AUTOSAR XML (schema 4-2-1)
package /MICROSAR/WdgM_swc/DataTypes
  5 x impl type, all with category=TYPE_REFERENCE:
    WdgM_SupervisedEntityIdType: range raw 0..65535, implementation-data-type=uint16  # Identifier of a supervised entity
    WdgM_CheckpointIdType: range raw 0..65535, implementation-data-type=uint16  # Identifier of a checkpoint
    WdgM_ModeType: range raw 0..255, implementation-data-type=uint8  # Identifier of the Watchdog trigger mode
    WdgM_LocalStatusType: compu {0=WDGM_LOCAL_STATUS_OK, 1=WDGM_LOCAL_STATUS_FAILED, 2=WDGM_LOCAL_STATUS_EXPIRED, 4=WDGM_LOCAL_STATUS_DEACTIVATED}, range raw 0..4, implementation-data-type=uint8  # Local Monitoring Status of a supervised entity.
    WdgM_GlobalStatusType: compu {0=WDGM_GLOBAL_STATUS_OK, 1=WDGM_GLOBAL_STATUS_FAILED, 2=WDGM_GLOBAL_STATUS_EXPIRED, 3=WDGM_GLOBAL_STATUS_STOPPED, 4=WDGM_GLOBAL_STATUS_DEACTIVATED}, range raw 0..4, implementation-data-type=uint8  # Global Monitoring Status summarizes all local monitoring statuses of all supervised entities.
package /MICROSAR/WdgM_swc/Interfaces
  client server interface WdgM_AliveSupervision: is-service=true, service-kind=WATCH-DOG-MANAGER
    operation CheckpointReached: possible-error=WdgM_AliveSupervision/E_NOT_OK  # Indicates to the Watchdog Manager that a Checkpoint within a Supervised Entity has been reached.
      arg CPID: type=WdgM_CheckpointIdType, direction=IN  # Identifier of the checkpoint within a supervised entity that has been reached.
    error E_NOT_OK: error-code=1
  client server interface WdgM_LocalStatus: is-service=true, service-kind=WATCH-DOG-MANAGER
    operation GetLocalStatus: possible-error=WdgM_LocalStatus/E_NOT_OK  # Returns the supervision status of a supervised entity.
      arg Status: type=WdgM_LocalStatusType, direction=OUT  # Supervision status of the given supervised entity.
    error E_NOT_OK: error-code=1
  client server interface WdgM_General: is-service=true, service-kind=WATCH-DOG-MANAGER
    6 x operation, all with possible-error=WdgM_General/E_NOT_OK:
      GetMode  # Returns the current mode of the Watchdog Manager.
        arg Mode: type=WdgM_ModeType, direction=OUT  # Current mode of the Watchdog Manager.
      GetGlobalStatus  # Returns the global supervision status of the Watchdog Manager.
        arg Status: type=WdgM_GlobalStatusType, direction=OUT  # Global supervision status of the Watchdog Manager.
      GetLocalStatus  # Returns the supervision status of a supervised entity.
        arg SEID: type=WdgM_SupervisedEntityIdType, direction=IN  # Identifier of the supervised entity whose supervision status shall be returned.
        arg Status: type=WdgM_LocalStatusType, direction=OUT  # Supervision status of the given supervised entity.
      PerformReset  # Instructs the Watchdog Manager to cause a watchdog reset.
      SetMode  # Requests a new trigger mode
        arg Mode: type=WdgM_ModeType, direction=IN  # Desired new trigger mode id.
        arg CallerID: type=uint16, direction=IN  # Module ID of the calling module.
      GetFirstExpiredSEID  # Returns the id of that supervised entity which first reached the status WDGM_LOCAL_STATUS_EXPIRED.
        arg SEID: type=WdgM_SupervisedEntityIdType, direction=OUT  # Pointer to a variable that stores the id of the supervised entity.
    error E_NOT_OK: error-code=1
package /MICROSAR/WdgM_swc/ComponentTypes
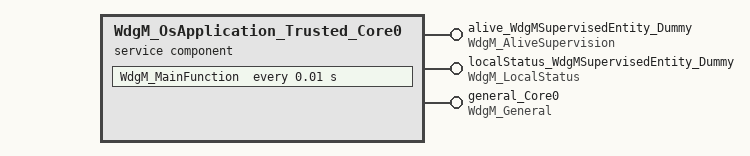
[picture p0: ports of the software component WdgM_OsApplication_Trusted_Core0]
  service sw component type WdgM_OsApplication_Trusted_Core0: category=SERVICE_COMPONENT
    provide port alive_WdgMSupervisedEntity_Dummy: provided-interface=WdgM_AliveSupervision  # Alive-P-Port Prototype for supervised entity 'WdgMSupervisedEntity_Dummy' with Id '0' for Application 'OsApplication_Trusted_Core0'.
    provide port localStatus_WdgMSupervisedEntity_Dummy: provided-interface=WdgM_LocalStatus  # P-Port Prototype for supervised entity 'WdgMSupervisedEntity_Dummy' with Id '0' for Application 'OsApplication_Trusted_Core0' to request the local status.
    provide port general_Core0: provided-interface=WdgM_General  # General P-Port-Prototype for core 0 (OsApplication_Trusted_Core0)
    behavior WdgM_OsApplication_Trusted_Core0InternalBehavior: handle-termination-and-restart=NO-SUPPORT
      operation invoked event OpEventCheckpointReached_CheckpointReached_alive_WdgMSupervisedEntity_Dummy: start-on-event=WdgM_OsApplication_Trusted_Core0InternalBehavior/CheckpointReached, operation=alive_WdgMSupervisedEntity_Dummy.CheckpointReached
      operation invoked event OpEventGetLocalStatus_GetLocalStatus_localStatus_WdgMSupervisedEntity_Dummy: start-on-event=WdgM_OsApplication_Trusted_Core0InternalBehavior/GetLocalStatus, operation=localStatus_WdgMSupervisedEntity_Dummy.GetLocalStatus
      timing event Timer_WdgM_MainFunction: start-on-event=WdgM_MainFunction, period=0.01
      6 x operation invoked event:
        OpEventGetLocalStatus_GetLocalStatus_general_Core0: start-on-event=WdgM_OsApplication_Trusted_Core0InternalBehavior/GetLocalStatus, operation=general_Core0.GetLocalStatus
        OpEventGetMode_GetMode_general_Core0: start-on-event=GetMode, operation=general_Core0.GetMode
        OpEventGetGlobalStatus_GetGlobalStatus_general_Core0: start-on-event=GetGlobalStatus, operation=general_Core0.GetGlobalStatus
        OpEventPerformReset_PerformReset_general_Core0: start-on-event=PerformReset, operation=general_Core0.PerformReset
        OpEventSetMode_SetMode_general_Core0: start-on-event=SetMode, operation=general_Core0.SetMode
        OpEventGetFirstExpiredSEID_GetFirstExpiredSEID_general_Core0: start-on-event=GetFirstExpiredSEID, operation=general_Core0.GetFirstExpiredSEID
      port-api-options:
        {enable-take-address=true, indirect-api=false, port-defined-argument-value{value=SEID:0, value-type=WdgM_SupervisedEntityIdType}, port=alive_WdgMSupervisedEntity_Dummy}
        {enable-take-address=true, indirect-api=false, port-defined-argument-value{value=0, value-type=WdgM_SupervisedEntityIdType}, port=localStatus_WdgMSupervisedEntity_Dummy}
        enable-take-address=true, indirect-api=false, port=general_Core0
      8 x runnable, all with can-be-invoked-concurrently=true:
        CheckpointReached: symbol=WdgM_CheckpointReached
        GetLocalStatus: symbol=WdgM_GetLocalStatus
        WdgM_MainFunction
        GetMode: symbol=WdgM_GetMode
        GetGlobalStatus: symbol=WdgM_GetGlobalStatus
        PerformReset: symbol=WdgM_PerformReset
        SetMode: symbol=WdgM_SetMode
        GetFirstExpiredSEID: symbol=WdgM_GetFirstExpiredSEID
  swc implementation WdgM_OsApplication_Trusted_Core0Implementation: programming-language=C, behavior=WdgM_OsApplication_Trusted_Core0InternalBehavior
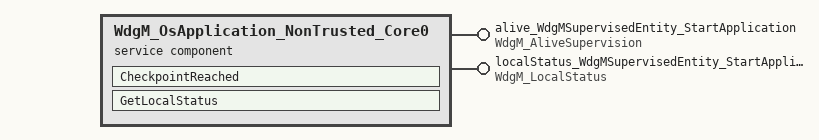
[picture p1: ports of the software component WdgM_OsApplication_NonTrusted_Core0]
  service sw component type WdgM_OsApplication_NonTrusted_Core0: category=SERVICE_COMPONENT
    provide port alive_WdgMSupervisedEntity_StartApplication: provided-interface=WdgM_AliveSupervision  # Alive-P-Port Prototype for supervised entity 'WdgMSupervisedEntity_StartApplication' with Id '1' for Application 'OsApplication_NonTrusted_Core0'.
    provide port localStatus_WdgMSupervisedEntity_StartApplication: provided-interface=WdgM_LocalStatus  # P-Port Prototype for supervised entity 'WdgMSupervisedEntity_StartApplication' with Id '1' for Application 'OsApplication_NonTrusted_Core0' to request the local status.
    behavior WdgM_OsApplication_NonTrusted_Core0InternalBehavior: handle-termination-and-restart=NO-SUPPORT
      operation invoked event OpEventCheckpointReached_CheckpointReached_alive_WdgMSupervisedEntity_StartApplication: start-on-event=WdgM_OsApplication_NonTrusted_Core0InternalBehavior/CheckpointReached, operation=alive_WdgMSupervisedEntity_StartApplication.CheckpointReached
      operation invoked event OpEventGetLocalStatus_GetLocalStatus_localStatus_WdgMSupervisedEntity_StartApplication: start-on-event=WdgM_OsApplication_NonTrusted_Core0InternalBehavior/GetLocalStatus, operation=localStatus_WdgMSupervisedEntity_StartApplication.GetLocalStatus
      port-api-options:
        {enable-take-address=true, indirect-api=false, port-defined-argument-value{value=SEID:1, value-type=WdgM_SupervisedEntityIdType}, port=alive_WdgMSupervisedEntity_StartApplication}
        {enable-take-address=true, indirect-api=false, port-defined-argument-value{value=1, value-type=WdgM_SupervisedEntityIdType}, port=localStatus_WdgMSupervisedEntity_StartApplication}
      runnable CheckpointReached: can-be-invoked-concurrently=true, symbol=WdgM_CheckpointReached
      runnable GetLocalStatus: can-be-invoked-concurrently=true, symbol=WdgM_GetLocalStatus
  swc implementation WdgM_OsApplication_NonTrusted_Core0Implementation: programming-language=C, behavior=WdgM_OsApplication_NonTrusted_Core0InternalBehavior
